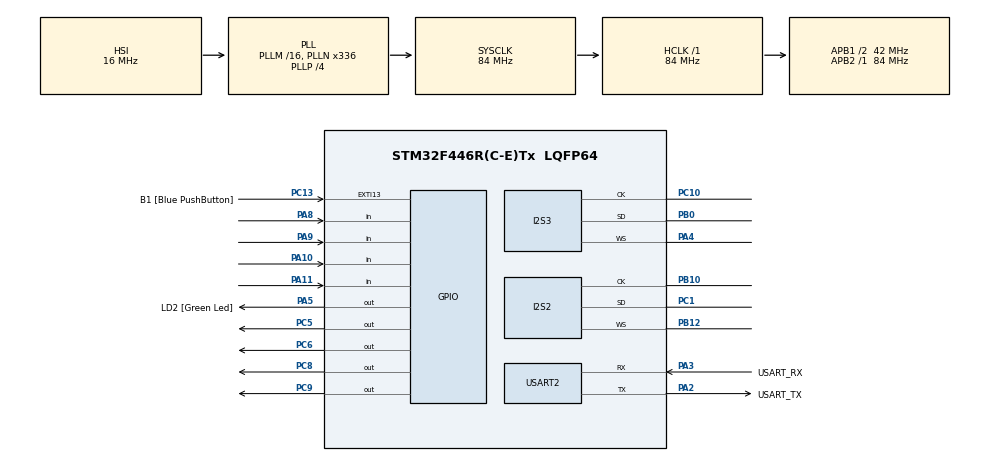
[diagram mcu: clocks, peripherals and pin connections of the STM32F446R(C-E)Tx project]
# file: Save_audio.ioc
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Dma.Request0=SPI2_TX
Dma.Request1=SPI3_RX
Dma.SPI2_TX.0.Direction=DMA_MEMORY_TO_PERIPH
Dma.SPI2_TX.0.FIFOMode=DMA_FIFOMODE_DISABLE
Dma.SPI2_TX.0.Instance=DMA1_Stream4
Dma.SPI2_TX.0.MemDataAlignment=DMA_MDATAALIGN_HALFWORD
Dma.SPI2_TX.0.MemInc=DMA_MINC_ENABLE
Dma.SPI2_TX.0.Mode=DMA_NORMAL
Dma.SPI2_TX.0.PeriphDataAlignment=DMA_PDATAALIGN_HALFWORD
Dma.SPI2_TX.0.PeriphInc=DMA_PINC_DISABLE
Dma.SPI2_TX.0.Priority=DMA_PRIORITY_LOW
Dma.SPI3_RX.1.Direction=DMA_PERIPH_TO_MEMORY
Dma.SPI3_RX.1.FIFOMode=DMA_FIFOMODE_DISABLE
Dma.SPI3_RX.1.Instance=DMA1_Stream0
Dma.SPI3_RX.1.MemDataAlignment=DMA_MDATAALIGN_HALFWORD
Dma.SPI3_RX.1.MemInc=DMA_MINC_ENABLE
Dma.SPI3_RX.1.Mode=DMA_NORMAL
Dma.SPI3_RX.1.PeriphDataAlignment=DMA_PDATAALIGN_HALFWORD
Dma.SPI3_RX.1.PeriphInc=DMA_PINC_DISABLE
Dma.SPI3_RX.1.Priority=DMA_PRIORITY_LOW
I2S2.AudioFreq=I2S_AUDIOFREQ_16K
I2S2.ErrorAudioFreq=-0.26 %
I2S2.FullDuplexMode=I2S_FULLDUPLEXMODE_DISABLE
I2S2.Instance=SPI$Index
I2S2.RealAudioFreq=15.957 KHz
I2S2.VirtualMode=I2S_MODE_MASTER
I2S3.AudioFreq=I2S_AUDIOFREQ_16K
I2S3.ErrorAudioFreq=-0.26 %
I2S3.FullDuplexMode=I2S_FULLDUPLEXMODE_DISABLE
I2S3.Instance=SPI$Index
I2S3.Mode=I2S_MODE_MASTER_RX
I2S3.RealAudioFreq=15.957 KHz
I2S3.VirtualMode=I2S_MODE_MASTER
Mcu.Family=STM32F4
Mcu.Name=STM32F446R(C-E)Tx
Mcu.Package=LQFP64
NVIC.DMA1_Stream0_IRQn=true\:0\:0\:false\:false\:true\:false\:true\:true
NVIC.DMA1_Stream4_IRQn=true\:0\:0\:false\:false\:true\:false\:true\:true
NVIC.PriorityGroup=NVIC_PRIORITYGROUP_0
PA10.Signal=GPIO_Input
PA11.Signal=GPIO_Input
PA13.GPIO_Label=TMS
PA13.Mode=Serial_Wire
PA13.Signal=SYS_JTMS-SWDIO
PA14.GPIO_Label=TCK
PA14.Mode=Serial_Wire
PA14.Signal=SYS_JTCK-SWCLK
PA2.GPIO_Label=USART_TX
PA2.Mode=Asynchronous
PA2.Signal=USART2_TX
PA3.GPIO_Label=USART_RX
PA3.Mode=Asynchronous
PA3.Signal=USART2_RX
PA4.Mode=Half_Duplex_Master
PA4.Signal=I2S3_WS
PA5.GPIO_Label=LD2 [Green Led]
PA5.Signal=GPIO_Output
PA8.Signal=GPIO_Input
PA9.Signal=GPIO_Input
PB0.Mode=Half_Duplex_Master
PB0.Signal=I2S3_SD
PB10.Mode=Half_Duplex_Master
PB10.Signal=I2S2_CK
PB12.Mode=Half_Duplex_Master
PB12.Signal=I2S2_WS
PB3.GPIO_Label=SWO
PB3.Signal=SYS_JTDO-SWO
PC1.Mode=Half_Duplex_Master
PC1.Signal=I2S2_SD
PC10.Mode=Half_Duplex_Master
PC10.Signal=I2S3_CK
PC13.GPIO_Label=B1 [Blue PushButton]
PC13.GPIO_ModeDefaultEXTI=GPIO_MODE_IT_FALLING
PC13.Signal=GPXTI13
PC14-OSC32_IN.Mode=LSE-External-Oscillator
PC14-OSC32_IN.Signal=RCC_OSC32_IN
PC15-OSC32_OUT.Mode=LSE-External-Oscillator
PC15-OSC32_OUT.Signal=RCC_OSC32_OUT
PC5.Signal=GPIO_Output
PC6.Signal=GPIO_Output
PC8.Signal=GPIO_Output
PC9.Signal=GPIO_Output
PH0-OSC_IN.Mode=HSE-External-Oscillator
PH0-OSC_IN.Signal=RCC_OSC_IN
PH1-OSC_OUT.Mode=HSE-External-Oscillator
PH1-OSC_OUT.Signal=RCC_OSC_OUT
ProjectManager.HeapSize=0x200
ProjectManager.StackSize=0x400
ProjectManager.TargetToolchain=STM32CubeIDE
RCC.48MHZClocksFreq_Value=84000000
RCC.AHBFreq_Value=84000000
RCC.APB1CLKDivider=RCC_HCLK_DIV2
RCC.APB1Freq_Value=42000000
RCC.APB1TimFreq_Value=84000000
RCC.APB2Freq_Value=84000000
RCC.APB2TimFreq_Value=84000000
RCC.CortexFreq_Value=84000000
RCC.FLatency-AdvancedSettings=FLASH_LATENCY_2
RCC.HCLKFreq_Value=84000000
RCC.HSE_VALUE=8000000
RCC.HSI_VALUE=16000000
RCC.PLLN=336
RCC.PLLP=RCC_PLLP_DIV4
RCC.SYSCLKFreq_VALUE=84000000
RCC.SYSCLKSource=RCC_SYSCLKSOURCE_PLLCLK
RCC.USBFreq_Value=168000000
RCC.VCOOutputFreq_Value=336000000
STMicroelectronics.X-CUBE-ALGOBUILD.1.4.0.LibraryCcDSPOoLibraryJjDSPOoLibrary=true
USART2.VirtualMode=VM_ASYNC
VP_STMicroelectronics.X-CUBE-ALGOBUILD_VS_DSPOoLibraryJjLibrary_1.4.0_1.4.0.Mode=DSPOoLibraryJjLibrary
board=NUCLEO-F446RE

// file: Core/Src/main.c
#include "main.h"
#include "arm_math.h"
#include "stdio.h"
#include <stdbool.h>
#include "string.h"

#define NUM_TAPS 16
float32_t low_cutoff = 0.0f;    //HZ
float32_t LOW_CUTOFF;
float32_t high_cutoff = 5000.0f;	//HZ
float32_t HIGH_CUTOFF;
int VOLUME = 1;
#define BLOCK_SIZE 1

I2S_HandleTypeDef hi2s2;
I2S_HandleTypeDef hi2s3;
DMA_HandleTypeDef hdma_spi2_tx;
DMA_HandleTypeDef hdma_spi3_rx;
UART_HandleTypeDef huart2;

void SystemClock_Config(void);
void PeriphCommonClock_Config(void);
static void MX_GPIO_Init(void);
static void MX_DMA_Init(void);
static void MX_USART2_UART_Init(void);
static void MX_I2S2_Init(void);
static void MX_I2S3_Init(void);
/* USER CODE BEGIN PFP */
int16_t toReceive;
int16_t toWrite;
arm_fir_instance_f32 S;
float32_t firCoeffs[NUM_TAPS]; // Filter coefficients
float32_t firState[NUM_TAPS + BLOCK_SIZE - 1]; // Filter state
float32_t filter_input;    // filter input
float32_t filter_output;   // filter output
float32_t phase_change = 100.0f;
bool active_mode_select = false;
bool setting_mode_select = false;
bool mode_button_pressed = false;
bool setting_button_pressed = false;
/* USER CODE END PFP */

/* USER CODE BEGIN 0 */

bool check_s1_pressed()
{
    static uint32_t last_press_time = 0;
    uint32_t current_time = HAL_GetTick();

    HAL_GPIO_WritePin(GPIOC, GPIO_PIN_6, GPIO_PIN_SET);

    bool pressed = false;
    if (HAL_GPIO_ReadPin(GPIOA, GPIO_PIN_8) == GPIO_PIN_SET)
    {
        if (current_time - last_press_time > 200)
        {
            pressed = true;
            last_press_time = current_time;
        }
    }
    HAL_GPIO_WritePin(GPIOC, GPIO_PIN_6, GPIO_PIN_RESET);

    return pressed;
}

bool check_specific_button_pressed(int button_id)
{
    int row, col;

    // Map button_id to row and column
    map_button_to_row_col(button_id, &row, &col);

    // Activate the specific row (R1~R4 -> PC6~PC9)
    HAL_GPIO_WritePin(GPIOC, 1 << (row + 6), GPIO_PIN_SET); // Set the corresponding row high

    // Check if the corresponding column (C1~C4 -> PA8~PA11) is high
    bool pressed = HAL_GPIO_ReadPin(GPIOA, 1 << (col + 8)) == GPIO_PIN_SET;

    // Reset the row to low
    HAL_GPIO_WritePin(GPIOC, 1 << (row + 6), GPIO_PIN_RESET);

    return pressed;
}

// Function to map a button ID to row and column
void map_button_to_row_col(int button_id, int *row, int *col)
{
    *row = (button_id - 1) / 4; // Calculate row (0 to 3)
    *col = (button_id - 1) % 4; // Calculate column (0 to 3)
}

void bandpass_fir(float32_t* coeffs, int num_taps, float low_cutoff, float high_cutoff)
{
    int M = num_taps - 1;
    for (int n = 0; n < num_taps; n++)
    {
        if (n == M / 2)
        {
            coeffs[n] = 2 * (high_cutoff - low_cutoff);
        }
        else
        {
            coeffs[n] = (sin(2 * PI * high_cutoff * (n - M / 2)) - sin(2 * PI * low_cutoff * (n - M / 2)))
                        / (PI * (n - M / 2));
            coeffs[n] *= (0.54 - 0.46 * cos(2 * PI * n / M)); 	// 使用 Hamming  ?
        }
    }
}

void lowpass_fir(float32_t* coeffs, int num_taps, float cutoff)
{
    int M = num_taps - 1;
    for (int n = 0; n < num_taps; n++)
    {
        if (n == M / 2)
        {
            coeffs[n] = 2 * cutoff;
        }
        else
        {
            coeffs[n] = sin(2 * PI * cutoff * (n - M / 2)) / (PI * (n - M / 2));
            coeffs[n] *= (0.54 - 0.46 * cos(2 * PI * n / M));  // 使用 Hamming  ?
        }
    }
}

void init_filter()
{
	LOW_CUTOFF = low_cutoff / 16000.0f;
	HIGH_CUTOFF = high_cutoff / 16000.0f;							//If using lowpass filter
    //bandpass_fir(firCoeffs, NUM_TAPS, LOW_CUTOFF, HIGH_CUTOFF);   //If using bandpass filter
	lowpass_fir(firCoeffs, NUM_TAPS, HIGH_CUTOFF);
	arm_fir_init_f32(&S, NUM_TAPS, firCoeffs, firState, BLOCK_SIZE);
}

char buffer[16];
void HAL_I2S_RxCpltCallback(I2S_HandleTypeDef *hi2s)
{
    //Check whether press blue button
    if (HAL_GPIO_ReadPin(B1_GPIO_Port, B1_Pin) == GPIO_PIN_RESET) // If pressed
    {
    	if (!mode_button_pressed) // If mode_button_pressed = false
    	        {
					active_mode_select = !active_mode_select; // Mode change
					if (active_mode_select){
						high_cutoff = phase_change;
					}else{
						high_cutoff = 10000.0f;
					}
					init_filter();
					mode_button_pressed = true;      // Button pressed
    	        }
    }else{
    	mode_button_pressed= false;
    }

    //Check S1 button
    if (check_s1_pressed()){
		if (!setting_button_pressed) // Debouncing
		{
			setting_mode_select = !setting_mode_select;    // Switch Setting Mode
			setting_button_pressed = true;
		}
	}else{
		setting_button_pressed = false;
	}

    //Set mode or work mode(monitor or active)
    if (setting_mode_select==false){
    	//Apply DSP Filter
    	filter_input = (float32_t)toReceive; // Transfer to float type
    	arm_fir_f32(&S, &filter_input, &filter_output, BLOCK_SIZE);
		//filter_output = toReceive;    // IF no filter apply

    	// Mode select
		if (active_mode_select)
		{
			//toWrite = toReceive * (-1);
			toWrite = (int16_t)(filter_output)* -(VOLUME);    //after bandpass filter
			//HAL_I2S_Transmit_DMA(&hi2s2, &toWrite, 1);
		}
    }else{
    	filter_output = 0;
    	// Adjust parameter
		static uint32_t last_adjust_time = 0;
		uint32_t current_time = HAL_GetTick();
		if (current_time - last_adjust_time > 200){    //Adjust every 200 ms
			//Adjusting volume
			if (check_specific_button_pressed(9)){   //Increase volume
				VOLUME++;}
			else if (check_specific_button_pressed(13)){  //Decrease volume
				VOLUME--;}
			//Adjusting frequency band
			else if (check_specific_button_pressed(11)){  // Increase lower cutoff frequency
				low_cutoff += 100.0f;}
			else if (check_specific_button_pressed(15)){  // Decrease lower cutoff frequency
				low_cutoff -= 100.0f;}
			else if (check_specific_button_pressed(12)){  // Increase higher cutoff frequency
				high_cutoff += 100.0f;}
			else if (check_specific_button_pressed(16)){  // Decrease higher cutoff frequency
				high_cutoff -= 100.0f;}
			init_filter();
			last_adjust_time = current_time; // Update last adjustment time
		}
    }
    int16_t transform_output = (int16_t)(filter_output);
    HAL_UART_Transmit(&huart2, (uint8_t *)&transform_output, sizeof(transform_output), HAL_MAX_DELAY);
    HAL_I2S_Receive_DMA(hi2s, &toReceive, 1);
}

char str[120];
int main(void)
{
  HAL_Init();

  /* Configure the system clock */
  SystemClock_Config();

  /* Configure the peripherals common clocks */
  PeriphCommonClock_Config();

  /* Initialize all configured peripherals */
  MX_GPIO_Init();
  MX_DMA_Init();
  MX_USART2_UART_Init();
  MX_I2S2_Init();
  MX_I2S3_Init();
  init_filter();
  /* USER CODE BEGIN 2 */
  HAL_I2S_Receive_DMA(&hi2s3, &toReceive, 1);
  /* USER CODE END 2 */

  /* Infinite loop */
  /* USER CODE BEGIN WHILE */
  while (1)
  {
  }
}

void SystemClock_Config(void)
{
  RCC_OscInitTypeDef RCC_OscInitStruct = {0};
  RCC_ClkInitTypeDef RCC_ClkInitStruct = {0};

  /** Configure the main internal regulator output voltage
  */
  __HAL_RCC_PWR_CLK_ENABLE();
  __HAL_PWR_VOLTAGESCALING_CONFIG(PWR_REGULATOR_VOLTAGE_SCALE3);

  /** Initializes the RCC Oscillators according to the specified parameters
  * in the RCC_OscInitTypeDef structure.
  */
  RCC_OscInitStruct.OscillatorType = RCC_OSCILLATORTYPE_HSI;
  RCC_OscInitStruct.HSIState = RCC_HSI_ON;
  RCC_OscInitStruct.HSICalibrationValue = RCC_HSICALIBRATION_DEFAULT;
  RCC_OscInitStruct.PLL.PLLState = RCC_PLL_ON;
  RCC_OscInitStruct.PLL.PLLSource = RCC_PLLSOURCE_HSI;
  RCC_OscInitStruct.PLL.PLLM = 16;
  RCC_OscInitStruct.PLL.PLLN = 336;
  RCC_OscInitStruct.PLL.PLLP = RCC_PLLP_DIV4;
  RCC_OscInitStruct.PLL.PLLQ = 2;
  RCC_OscInitStruct.PLL.PLLR = 2;
  if (HAL_RCC_OscConfig(&RCC_OscInitStruct) != HAL_OK)
  {
    Error_Handler();
  }

  /** Initializes the CPU, AHB and APB buses clocks
  */
  RCC_ClkInitStruct.ClockType = RCC_CLOCKTYPE_HCLK|RCC_CLOCKTYPE_SYSCLK
                              |RCC_CLOCKTYPE_PCLK1|RCC_CLOCKTYPE_PCLK2;
  RCC_ClkInitStruct.SYSCLKSource = RCC_SYSCLKSOURCE_PLLCLK;
  RCC_ClkInitStruct.AHBCLKDivider = RCC_SYSCLK_DIV1;
  RCC_ClkInitStruct.APB1CLKDivider = RCC_HCLK_DIV2;
  RCC_ClkInitStruct.APB2CLKDivider = RCC_HCLK_DIV1;

  if (HAL_RCC_ClockConfig(&RCC_ClkInitStruct, FLASH_LATENCY_2) != HAL_OK)
  {
    Error_Handler();
  }
}

void PeriphCommonClock_Config(void)
{
  RCC_PeriphCLKInitTypeDef PeriphClkInitStruct = {0};

  /** Initializes the peripherals clock
  */
  PeriphClkInitStruct.PeriphClockSelection = RCC_PERIPHCLK_I2S_APB1;
  PeriphClkInitStruct.PLLI2S.PLLI2SN = 192;
  PeriphClkInitStruct.PLLI2S.PLLI2SP = RCC_PLLI2SP_DIV2;
  PeriphClkInitStruct.PLLI2S.PLLI2SM = 16;
  PeriphClkInitStruct.PLLI2S.PLLI2SR = 2;
  PeriphClkInitStruct.PLLI2S.PLLI2SQ = 2;
  PeriphClkInitStruct.PLLI2SDivQ = 1;
  PeriphClkInitStruct.I2sApb1ClockSelection = RCC_I2SAPB1CLKSOURCE_PLLI2S;
  if (HAL_RCCEx_PeriphCLKConfig(&PeriphClkInitStruct) != HAL_OK)
  {
    Error_Handler();
  }
}

static void MX_I2S2_Init(void)
{

  hi2s2.Instance = SPI2;
  hi2s2.Init.Mode = I2S_MODE_MASTER_TX;
  hi2s2.Init.Standard = I2S_STANDARD_PHILIPS;
  hi2s2.Init.DataFormat = I2S_DATAFORMAT_16B;
  hi2s2.Init.MCLKOutput = I2S_MCLKOUTPUT_DISABLE;
  hi2s2.Init.AudioFreq = I2S_AUDIOFREQ_16K;
  hi2s2.Init.CPOL = I2S_CPOL_LOW;
  hi2s2.Init.ClockSource = I2S_CLOCK_PLL;
  hi2s2.Init.FullDuplexMode = I2S_FULLDUPLEXMODE_DISABLE;
  if (HAL_I2S_Init(&hi2s2) != HAL_OK)
  {
    Error_Handler();
  }

}

static void MX_I2S3_Init(void)
{
  hi2s3.Instance = SPI3;
  hi2s3.Init.Mode = I2S_MODE_MASTER_RX;
  hi2s3.Init.Standard = I2S_STANDARD_PHILIPS;
  hi2s3.Init.DataFormat = I2S_DATAFORMAT_16B;
  hi2s3.Init.MCLKOutput = I2S_MCLKOUTPUT_DISABLE;
  hi2s3.Init.AudioFreq = I2S_AUDIOFREQ_16K;
  hi2s3.Init.CPOL = I2S_CPOL_LOW;
  hi2s3.Init.ClockSource = I2S_CLOCK_PLL;
  hi2s3.Init.FullDuplexMode = I2S_FULLDUPLEXMODE_DISABLE;
  if (HAL_I2S_Init(&hi2s3) != HAL_OK)
  {
    Error_Handler();
  }
}

static void MX_USART2_UART_Init(void)
{
  huart2.Instance = USART2;
  huart2.Init.BaudRate = 921600;//115200;
  huart2.Init.WordLength = UART_WORDLENGTH_8B;
  huart2.Init.StopBits = UART_STOPBITS_1;
  huart2.Init.Parity = UART_PARITY_NONE;
  huart2.Init.Mode = UART_MODE_TX_RX;
  huart2.Init.HwFlowCtl = UART_HWCONTROL_NONE;
  huart2.Init.OverSampling = UART_OVERSAMPLING_16;
  if (HAL_UART_Init(&huart2) != HAL_OK)
  {
    Error_Handler();
  }
}

static void MX_DMA_Init(void)
{

  /* DMA controller clock enable */
  __HAL_RCC_DMA1_CLK_ENABLE();

  /* DMA interrupt init */
  /* DMA1_Stream0_IRQn interrupt configuration */
  HAL_NVIC_SetPriority(DMA1_Stream0_IRQn, 0, 0);
  HAL_NVIC_EnableIRQ(DMA1_Stream0_IRQn);
  /* DMA1_Stream4_IRQn interrupt configuration */
  HAL_NVIC_SetPriority(DMA1_Stream4_IRQn, 0, 0);
  HAL_NVIC_EnableIRQ(DMA1_Stream4_IRQn);

}

static void MX_GPIO_Init(void)
{
  GPIO_InitTypeDef GPIO_InitStruct = {0};

  /* GPIO Ports Clock Enable */
  __HAL_RCC_GPIOC_CLK_ENABLE();
  __HAL_RCC_GPIOH_CLK_ENABLE();
  __HAL_RCC_GPIOA_CLK_ENABLE();
  __HAL_RCC_GPIOB_CLK_ENABLE();

  /*Configure GPIO pin Output Level */
  HAL_GPIO_WritePin(LD2_GPIO_Port, LD2_Pin, GPIO_PIN_RESET);

  /*Configure GPIO pin Output Level */
  HAL_GPIO_WritePin(GPIOC, GPIO_PIN_6|GPIO_PIN_5|GPIO_PIN_8|GPIO_PIN_9, GPIO_PIN_RESET);

  /*Configure GPIO pin : B1_Pin */
  GPIO_InitStruct.Pin = B1_Pin;
  GPIO_InitStruct.Mode = GPIO_MODE_IT_FALLING;
  GPIO_InitStruct.Pull = GPIO_NOPULL;
  HAL_GPIO_Init(B1_GPIO_Port, &GPIO_InitStruct);

  /*Configure GPIO pin : LD2_Pin */
  GPIO_InitStruct.Pin = LD2_Pin;
  GPIO_InitStruct.Mode = GPIO_MODE_OUTPUT_PP;
  GPIO_InitStruct.Pull = GPIO_NOPULL;
  GPIO_InitStruct.Speed = GPIO_SPEED_FREQ_LOW;
  HAL_GPIO_Init(LD2_GPIO_Port, &GPIO_InitStruct);

  /*Configure GPIO pins : PC6 PC7 PC8 PC9 */
  GPIO_InitStruct.Pin = GPIO_PIN_6|GPIO_PIN_5|GPIO_PIN_8|GPIO_PIN_9;
  GPIO_InitStruct.Mode = GPIO_MODE_OUTPUT_PP;
  GPIO_InitStruct.Pull = GPIO_NOPULL;
  GPIO_InitStruct.Speed = GPIO_SPEED_FREQ_LOW;
  HAL_GPIO_Init(GPIOC, &GPIO_InitStruct);

  /*Configure GPIO pins : PA8 PA9 PA10 PA11 */
  GPIO_InitStruct.Pin = GPIO_PIN_8|GPIO_PIN_9|GPIO_PIN_10|GPIO_PIN_11;
  GPIO_InitStruct.Mode = GPIO_MODE_INPUT;
  GPIO_InitStruct.Pull = GPIO_PULLDOWN;
  HAL_GPIO_Init(GPIOA, &GPIO_InitStruct);
}

void Error_Handler(void)
{
  /* USER CODE BEGIN Error_Handler_Debug */
  /* User can add his own implementation to report the HAL error return state */
  __disable_irq();
  while (1)
  {
  }
}
